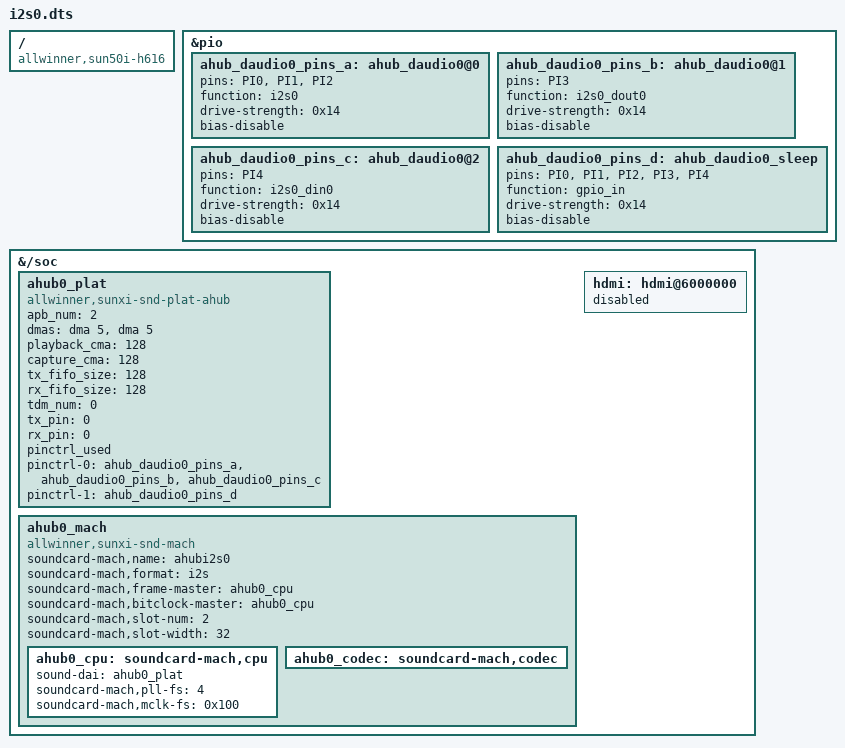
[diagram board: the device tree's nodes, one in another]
/dts-v1/;
/plugin/;
/ {
    compatible = "allwinner,sun50i-h616";
    fragment@0 {
        target = <&pio>;
        __overlay__ {
            ahub_daudio0_pins_a: ahub_daudio0@0 {
                pins = "PI0", "PI1", "PI2";
                function = "i2s0";
                drive-strength = <0x14>;
                bias-disable;
            }; 
            ahub_daudio0_pins_b: ahub_daudio0@1 {
                pins = "PI3";
                function = "i2s0_dout0";
                drive-strength = <0x14>;
                bias-disable;
            };
            ahub_daudio0_pins_c: ahub_daudio0@2 {
                pins = "PI4";
                function = "i2s0_din0";
	        drive-strength = <0x14>;
		bias-disable;
            };
            ahub_daudio0_pins_d: ahub_daudio0_sleep {
		pins = "PI0", "PI1", "PI2", "PI3", "PI4";
		function = "gpio_in";
		drive-strength = <0x14>;
        	bias-disable;
            };
        };
    };
    fragment@1 {
        target-path = "/soc";
        __overlay__ {
            ahub0_plat: ahub0_plat {
                #sound-dai-cells = <0>;
		compatible	= "allwinner,sunxi-snd-plat-ahub";
                apb_num		= <2>;	/* for dma port 5 */
		dmas		= <&dma 5>, <&dma 5>;
		dma-names	= "tx", "rx";
		playback_cma	= <128>;
		capture_cma	= <128>;
		tx_fifo_size	= <128>;
		rx_fifo_size	= <128>;
                tdm_num         = <0>;
                tx_pin          = <0>;
                rx_pin          = <0>;

		pinctrl-names = "default", "sleep";
                pinctrl_used;
		pinctrl-0 = <&ahub_daudio0_pins_a>, <&ahub_daudio0_pins_b>, <&ahub_daudio0_pins_c>;
		pinctrl-1 = <&ahub_daudio0_pins_d>;

                status = "okay";
            };
            ahub0_mach: ahub0_mach {
                compatible = "allwinner,sunxi-snd-mach";
		soundcard-mach,name = "ahubi2s0";
		soundcard-mach,format = "i2s";
                soundcard-mach,frame-master = <&ahub0_cpu>;
                soundcard-mach,bitclock-master = <&ahub0_cpu>;
                soundcard-mach,slot-num         = <2>;
                soundcard-mach,slot-width       = <32>;

		status = "okay";

                ahub0_cpu: soundcard-mach,cpu {
		    sound-dai = <&ahub0_plat>;
                    soundcard-mach,pll-fs   = <4>;
                    soundcard-mach,mclk-fs  = <0x100>;
		};

		ahub0_codec: soundcard-mach,codec {
		};
            };
            hdmi: hdmi@6000000 {
                status = "disabled";
            };
        };
    };
}; 
